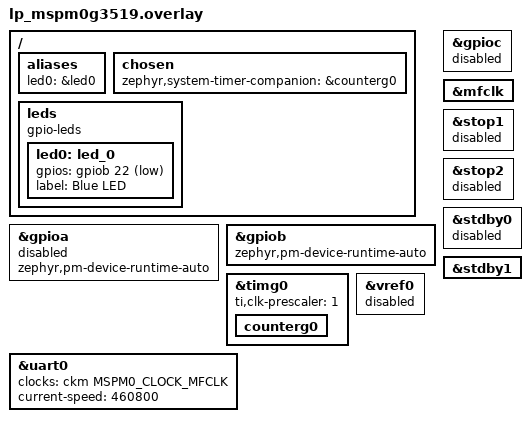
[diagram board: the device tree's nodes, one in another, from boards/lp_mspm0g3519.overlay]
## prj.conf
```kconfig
CONFIG_GPIO=y

# Low power
CONFIG_PM=y
CONFIG_PM_DEVICE=y
CONFIG_PM_DEVICE_RUNTIME=y
CONFIG_PM_DEVICE_RUNTIME_DEFAULT_ENABLE=y
CONFIG_PM_POLICY_DEFAULT=y
CONFIG_IDLE_STACK_SIZE=256
CONFIG_SYSTEM_TIMER_LPM_COMPANION_COUNTER=y
CONFIG_COUNTER=y
CONFIG_PM_PREWAKEUP_CONV_MODE_CEIL=y
CONFIG_SYS_CLOCK_EXISTS=y
CONFIG_SYSTEM_CLOCK_HW_CYCLES_PER_SEC_RUNTIME_UPDATE=y
```

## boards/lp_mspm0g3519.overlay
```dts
/*
 * Copyright (c) 2026 Texas Instruments
 *
 * SPDX-License-Identifier: Apache-2.0
 */

/ {
	aliases {
		led0 = &led0;
	};

	chosen {
		zephyr,system-timer-companion = &counterg0;
	};

	leds {
		compatible = "gpio-leds";

		led0: led_0 {
			gpios = <&gpiob 22 GPIO_ACTIVE_LOW>;
			label = "Blue LED";
		};
	};
};

&gpioa {
	status = "disabled";
	zephyr,pm-device-runtime-auto;
};

&gpiob {
	status = "okay";
	zephyr,pm-device-runtime-auto;
};

&gpioc {
	status = "disabled";
};

&timg0 {
	status = "okay";
	ti,clk-prescaler = <1>;

	counterg0 {
		status = "okay";
	};
};

&mfclk {
	status = "okay";
};

&uart0 {
	clocks = <&ckm MSPM0_CLOCK_MFCLK>;
	current-speed = <460800>;
};

&stop1 {
	status = "disabled";
};

&stop2 {
	status = "disabled";
};

&stdby0 {
	status = "disabled";
};

&stdby1 {
	status = "okay";
};

&vref0 {
	status = "disabled";
};
```

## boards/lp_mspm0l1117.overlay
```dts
/*
 * Copyright (c) 2026 Texas Instruments
 *
 * SPDX-License-Identifier: Apache-2.0
 */
 
/ {
	aliases {
		led0 = &led0;
	};

	chosen {
		zephyr,system-timer-companion = &counterg0;
	};

	leds {
		compatible = "gpio-leds";

		led0: led_0 {
			gpios = <&gpiob 16 GPIO_ACTIVE_HIGH>;
			label = "Blue LED";
		};
	};
};

&gpiob {
	status = "okay";
	zephyr,pm-device-runtime-auto;
};

&timg0 {
	status = "okay";

	counterg0 {
		status = "okay";
	};
};
```

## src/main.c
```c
/*
 * Copyright (c) 2016 Intel Corporation
 * Copyright (c) 2026 Texas Instruments
 *
 * SPDX-License-Identifier: Apache-2.0
 */

#include <stdio.h>
#include <zephyr/kernel.h>
#include <zephyr/drivers/gpio.h>
#include <zephyr/drivers/clock_control/mspm0_clock_control.h>
#include <ti/driverlib/driverlib.h>

/* 1000 msec = 1 sec */
#define SLEEP_TIME_MS   6

/* PA22 for CLK_OUT */
#define GPIO_CLKOUT_PIN                                           DL_GPIO_PIN_22
#define GPIO_CLKOUT_IOMUX                                        (IOMUX_PINCM47)
#define GPIO_CLKOUT_IOMUX_FUNC                   IOMUX_PINCM47_PF_SYSCTL_CLK_OUT
#define GPIO_CLKOUT_PORT                                                   GPIOA

/*
 * A build error on this line means your board is unsupported.
 * See the sample documentation for information on how to fix this.
 */
#define LED0_NODE DT_ALIAS(led0)
static const struct gpio_dt_spec led = GPIO_DT_SPEC_GET(LED0_NODE, gpios);

int main(void)
{
	int ret;
	bool led_state = true;

	DL_GPIO_enablePower(GPIOA);
	delay_cycles(16);
	DL_GPIO_initPeripheralOutputFunction(GPIO_CLKOUT_IOMUX, GPIO_CLKOUT_IOMUX_FUNC);
	DL_GPIO_enableOutput(GPIO_CLKOUT_PORT, GPIO_CLKOUT_PIN);
	DL_SYSCTL_enableExternalClock(DL_SYSCTL_CLK_OUT_SOURCE_ULPCLK, DL_SYSCTL_CLK_OUT_DIVIDE_16);

	if (!gpio_is_ready_dt(&led)) {
		return 0;
	}

	ret = gpio_pin_configure_dt(&led, GPIO_OUTPUT_ACTIVE);
	if (ret < 0) {
		return 0;
	}

	while (1) {

		ret = gpio_pin_toggle_dt(&led);
		if (ret < 0) {
			return 0;
		}

		/* During this k_msleep(), the PM policy manager automatically
		 * selects an appropriate SoC sleep state and the system enters
		 * low-power mode. Timer interrupt wakes the system after 1000ms.
		 */
		k_msleep(SLEEP_TIME_MS);
	}
	return 0;
}
```
